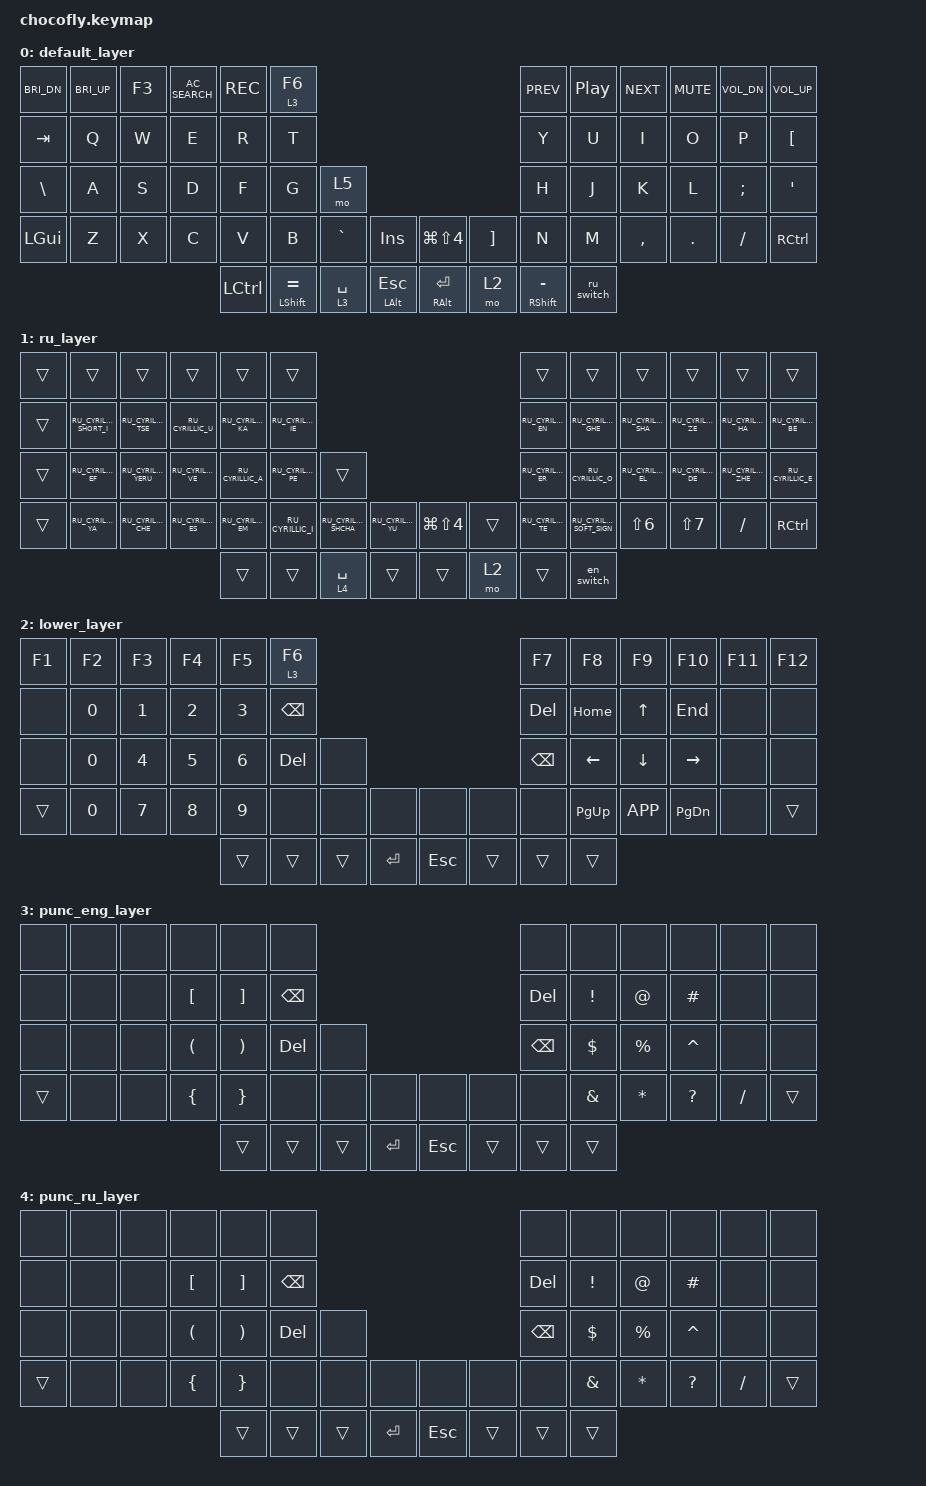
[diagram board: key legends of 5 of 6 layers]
#define ZMK_POINTING_DEFAULT_SCRL_VAL 100

#include <behaviors.dtsi>
#include <dt-bindings/zmk/keys.h>
#include <dt-bindings/zmk/bt.h>
#include <dt-bindings/zmk/pointing.h>
#include "keys_ru.h"

&lt { quick_tap_ms = <200>; };
&mt { quick_tap_ms = <200>; };
&msc {
        x-input-code = <INPUT_REL_HWHEEL>;
        y-input-code = <INPUT_REL_WHEEL>;
        time-to-max-speed-ms = <100>;
        acceleration-exponent = <1>;
        delay-ms = <0>;
        trigger-period-ms = <4>;
    };

/ {
    behaviors {
        
        scroll_encoder: scroll_encoder {
            compatible = "zmk,behavior-sensor-rotate-var";
            #sensor-binding-cells = <2>;
            bindings = <&msc>, <&msc>;
            tap-ms = <60>;
        };

        // Custom macro to switch to Russian layer and switch language
        ru_switch: ru_switch {
            compatible = "zmk,behavior-macro";
            #binding-cells = <0>;
            bindings =  <&macro_tap &kp LC(LS(S))>, <&macro_tap &to 1>;
            tap-ms = <100>;
        };

        // Custom macro to switch to English layer and switch language
        en_switch: en_switch {
            compatible = "zmk,behavior-macro";
            #binding-cells = <0>;
            bindings =  <&macro_tap &kp LC(LS(W))>, <&macro_tap &to 0>;
            tap-ms = <100>;
        };
    };
    
    keymap {
        compatible = "zmk,keymap";

        default_layer { // Layer 0 ENG
// ----------------------------------------------------------------------------------                                                -----------------------------------------------------------------------
// | C_BRI_DN|   C_BRI_UP   |    F3   | C_AC_SEARCH |   C_REC      |  F6            |                                                |  K_PREV       |  K_PP  |  K_NEXT  |  K_MUTE  | K_VOL_DN  | K_VOL_UP |
// |   TAB   |      Q       |    W    |      E      |   R          |  T             |-----------                                     |  Y            |   U    |    I     |     O    |    P      |    [     |
// |   \     |      A       |    S    |      D      |   F          |  G             | BT_LAYER |-------------------------------------|  H            |   J    |    K     |     L    |    ;      |    '     |
// |   GUI   |      Z       |    X    |      C      |   V          |  B             |   GRAVE  |   INSERT   |   PSCRN       |    ]   |  N            |   M    |    ,     |     .    |    /      |  R CTRL  |
// -------------------------------------------------|   CTRL       |  SHIFT         |   SPACE  |   ESCAPE   |   ENTER       |    FN  |  R SHIFT      | RU_LAY |---------------------------------------------
//                                                  ---------------------------------------------------------------------------------------------------------
           bindings = <
    &kp C_BRI_DN  &kp C_BRI_UP &kp F3  &kp C_AC_SEARCH &kp C_REC     &lt 3 F6                                                         &kp C_PREV      &kp C_PP &kp C_NEXT &kp K_MUTE &kp K_VOL_DN &kp K_VOL_UP
    &kp TAB       &kp Q        &kp W   &kp E           &kp R         &kp T                                                            &kp Y           &kp U    &kp I      &kp O      &kp P        &kp LBKT
    &kp BSLH      &kp A        &kp S   &kp D           &kp F         &kp G           &mo 5                                            &kp H           &kp J    &kp K      &kp L      &kp SEMI     &kp SQT
    &kp LGUI      &kp Z        &kp X   &kp C           &kp V         &kp B           &kp GRAVE   &kp INS      &kp LG(LS(N4)) &kp RBKT &kp N           &kp M    &kp COMMA  &kp DOT    &kp FSLH     &kp RCTRL
                                                       &kp LCTRL     &mt LSHFT EQUAL &lt 3 SPACE &mt LALT ESC &mt RALT RET   &mo 2    &mt RSHFT MINUS &ru_switch
            >;
            sensor-bindings = <&scroll_encoder SCRL_UP SCRL_DOWN>;
        };

        ru_layer { // Layer 1 RU
// ------------------------------------------------------------------------------------------------------------------------------------                                                                        ------------------------------------------------------------------------------------------------------------------------------------
// |     C_BRI_DN           |        C_BRI_UP       |        F3            |    C_AC_SEARCH    |      C_REC       |        F6         |                                                                        |        K_PREV     |          K_PP             |          K_NEXT       |       K_MUTE      |      K_VOL_DN     |     K_VOL_UP     |
// |        -               |           й           |         ц            |       у           |        к         |        е          |-------------------                                                     |        н          |           г               |            ш          |         з         |         х         |        б         |
// |        -               |           ф           |         ы            |       в           |        а         |        п          |        -         |-----------------------------------------------------|        р          |           о               |            л          |         д         |         ж         |        э         |
// |        -               |           я           |         ч            |       с           |        м         |        и          |        щ         |        ю           |       PSCRN        |     ъ     |        т          |           ь               |            ,          |         .         |         /         |        -         |
// --------------------------------------------------------------------------------------------|        -         |        -          |      SPACE       |     ESCAPE         |       ENTER        |    FN     |        -          |         ENG_LAY           |-----------------------------------------------------------------------------------
//                                                                                             -----------------------------------------------------------------------------------------------------------------------------------------------------------------
            bindings = <
            &trans                  &trans                &trans            &trans              &trans              &trans                                                                                    &trans               &trans                     &trans                  &trans              &trans               &trans
            &trans           &kp RU_CYRILLIC_SHORT_I  &kp RU_CYRILLIC_TSE   &kp RU_CYRILLIC_U   &kp RU_CYRILLIC_KA  &kp RU_CYRILLIC_IE                                                                        &kp RU_CYRILLIC_EN   &kp RU_CYRILLIC_GHE        &kp RU_CYRILLIC_SHA     &kp RU_CYRILLIC_ZE  &kp RU_CYRILLIC_HA   &kp RU_CYRILLIC_BE
            &trans           &kp RU_CYRILLIC_EF       &kp RU_CYRILLIC_YERU  &kp RU_CYRILLIC_VE  &kp RU_CYRILLIC_A   &kp RU_CYRILLIC_PE  &trans                                                                &kp RU_CYRILLIC_ER   &kp RU_CYRILLIC_O          &kp RU_CYRILLIC_EL      &kp RU_CYRILLIC_DE  &kp RU_CYRILLIC_ZHE  &kp RU_CYRILLIC_E   
            &trans           &kp RU_CYRILLIC_YA       &kp RU_CYRILLIC_CHE   &kp RU_CYRILLIC_ES  &kp RU_CYRILLIC_EM  &kp RU_CYRILLIC_I   &kp RU_CYRILLIC_SHCHA  &kp RU_CYRILLIC_YU  &kp LG(LS(N4))   &trans    &kp RU_CYRILLIC_TE   &kp RU_CYRILLIC_SOFT_SIGN  &kp LS(N6)              &kp LS(N7)          &kp SLASH            &kp RCTRL  
                                                                                                &trans              &trans              &lt 4 SPACE            &trans              &trans           &mo 2     &trans               &en_switch
            >;
            sensor-bindings = <&scroll_encoder SCRL_UP SCRL_DOWN>;
        };

        lower_layer { // Layer 2  nums and arrows
// -------------------------------------------------------------                                       -------------------------------------------------------------
// |   F1    |    F2   |    F3   |    F4   |  F5     |  F6     |                                       |  F7     |    F8   |    F9   |   F10   |   F11   |    F12  |
// |         |    0    |    1    |    2    |    3    |  BSPC   |----------                             |  DEL    |   HOME  |   UP    |  END    |         |         |
// |         |    0    |    4    |    5    |    6    |  DEL    |         |-----------------------------|  BSPC   |   LEFT  |   DOWN  |  RIGHT  |         |         |
// |    -    |    0    |    7    |    8    |    9    |         |         |         |         |         |         |   PG UP | APP MENU| PG DOWN |         |    -    |
// ----------------------------------------|    -    |  -      |    -    |  ENTER  | ESCAPE  |    -    |    -    |    -    |----------------------------------------
//                                         ---------------------------------------------------------------------------------
            bindings = <
    &kp F1        &kp F2   &kp F3   &kp F4    &kp F5    &lt 3 F6                                       &kp F7      &kp F8     &kp F9     &kp F10    &kp F11 &kp F12
    &none         &kp N0   &kp N1   &kp N2    &kp N3    &kp BSPC                                       &kp DEL     &kp HOME   &kp UP     &kp END    &none   &none
    &none         &kp N0   &kp N4   &kp N5    &kp N6    &kp DEL   &none                                &kp BSPC    &kp LEFT   &kp DOWN   &kp RIGHT  &none   &none
    &trans        &kp N0   &kp N7   &kp N8    &kp N9    &none     &none   &none    &none     &none     &none       &kp PG_UP  &kp K_APP  &kp PG_DN  &none   &trans
                                              &trans    &trans    &trans  &kp RET  &kp ESC   &trans    &trans      &trans
            >;
            sensor-bindings = <&scroll_encoder SCRL_UP SCRL_DOWN>;
        };

        punc_eng_layer { // Layer 3 ENG punctuation marks
// -------------------------------------------------------------                                        -------------------------------------------------------------
// |         |         |         |         |         |         |                                       |         |         |         |         |         |         |
// |         |         |         |    [    |    ]    |    BSPC |----------                             |  DEL    |    !    |    @    |    #    |         |         |
// |         |         |         |    (    |    )    |    DEL  |         |-----------------------------|  BSPC   |    $    |    %    |    ^    |         |         |
// |    -    |         |         |    {    |    }    |         |         |         |         |         |         |    &    |    *    |    ?    |    /    |    -    |
// ----------------------------------------|    -    |    -    |    -    |  ENTER  | ESCAPE  |    -    |    -    |    -    |----------------------------------------
//                                         ---------------------------------------------------------------------------------
            bindings = <
    &none         &none    &none    &none     &none     &none                                          &none      &none     &none     &none       &none      &none
    &none         &none    &none    &kp LBKT  &kp RBKT  &kp BSPC                                       &kp DEL    &kp EXCL  &kp AT    &kp HASH    &none      &none
    &none         &none    &none    &kp LPAR  &kp RPAR  &kp DEL   &none                                &kp BSPC   &kp DLLR  &kp PRCNT &kp CARET   &none      &none
    &trans        &none    &none    &kp LBRC  &kp RBRC  &none     &none   &none    &none     &none     &none      &kp AMPS  &kp ASTRK &kp QMARK   &kp FSLH   &trans
                                              &trans    &trans    &trans  &kp RET  &kp ESC   &trans    &trans     &trans
            >;
            sensor-bindings = <&scroll_encoder SCRL_UP SCRL_DOWN>;
        };


        punc_ru_layer { // Layer 4 RU punctuation marks
// -------------------------------------------------------------                                        -------------------------------------------------------------
// |         |         |         |         |         |         |                                       |         |         |         |         |         |         |
// |         |         |         |    [    |    ]    |    BSPC |----------                             |  DEL    |    !    |    @    |    #    |         |         |
// |         |         |         |    (    |    )    |    DEL  |         |-----------------------------|  BSPC   |    $    |    %    |    ^    |         |         |
// |    -    |         |         |    {    |    }    |         |         |         |         |         |         |    &    |    *    |    ?    |    /    |    -    |
// ----------------------------------------|    -    |    -    |    -    |  ENTER  | ESCAPE  |    -    |    -    |    -    |----------------------------------------
//                                         ---------------------------------------------------------------------------------
            bindings = <
    &none         &none    &none    &none     &none     &none                                          &none      &none     &none     &none       &none      &none
    &none         &none    &none    &kp LBKT  &kp RBKT  &kp BSPC                                       &kp DEL    &kp EXCL  &kp AT    &kp HASH    &none      &none
    &none         &none    &none    &kp LPAR  &kp RPAR  &kp DEL   &none                                &kp BSPC   &kp DLLR  &kp PRCNT &kp CARET   &none      &none
    &trans        &none    &none    &kp LBRC  &kp RBRC  &none     &none   &none    &none     &none     &none      &kp AMPS  &kp ASTRK &kp QMARK   &kp FSLH   &trans
                                              &trans    &trans    &trans  &kp RET  &kp ESC   &trans    &trans     &trans
            >;
            sensor-bindings = <&scroll_encoder SCRL_UP SCRL_DOWN>;
        };


        ble_layer { // Layer 5 Bluetouth settings 
// -------------------------------------------------------------------------                                       -------------------------------------------------------------
// |  BT_SEL 0  |  BT_SEL 1  |  BT_SEL 2  |         | BT_CLR_ALL | BT_CLR  |                                       | BT_PRV  |         | BT_NXT  |         |         | BT_DISC |
// |            |            |            |         |            |         |----------                             |         |         |         |         |         |         |
// |            |            |            |         |            |         |         |-----------------------------|         |         |         |         |         |         |
// |    -       |            |            |         |            |         |         |  STUDIO |         |         |         |         |         |         |         |    -    |
// ---------------------------------------|     -   |    -       |    -    |    -    |    -    |    -    |    -    |    -    |--------------------------------------------------
//                                        ------------------------------------------------------------------------------------
            bindings = <
    &bt BT_SEL 0  &bt BT_SEL 1  &bt BT_SEL 2  &none    &bt BT_CLR_ALL &bt BT_CLR                                &bt BT_PRV &none    &bt BT_NXT  &none    &none   &bt BT_DISC
    &none        &none    &none    &none      &none       &none                                                 &none      &none    &none       &none    &none    &none
    &none        &none    &none    &none      &none       &none                                                 &none      &none    &none       &none    &none    &none
    &trans       &none    &none    &none      &none       &none     &none      &none    &studio_unlock  &none   &none      &none    &none       &none    &none    &trans
                                              &trans      &trans    &trans     &trans   &trans          &trans  &trans     &trans
            >;
            sensor-bindings = <&scroll_encoder SCRL_UP SCRL_DOWN>;
        };
    };
};
